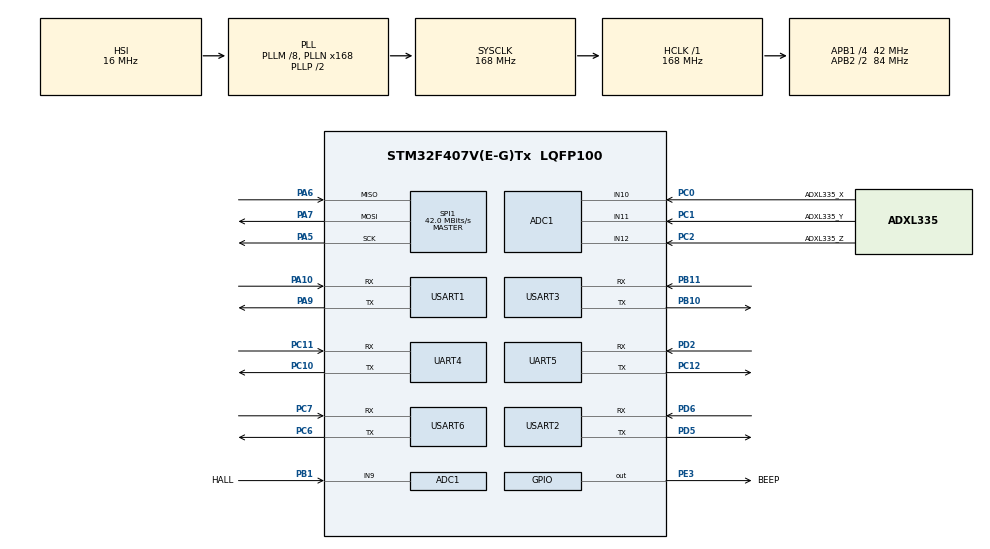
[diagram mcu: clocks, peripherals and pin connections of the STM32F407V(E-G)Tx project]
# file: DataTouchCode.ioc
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ADC1.Channel-0\#ChannelRegularConversion=ADC_CHANNEL_10
ADC1.NbrOfConversionFlag=1
ADC1.Rank-0\#ChannelRegularConversion=1
ADC1.SamplingTime-0\#ChannelRegularConversion=ADC_SAMPLETIME_3CYCLES
ADC1.master=1
Dma.Request0=UART5_RX
Dma.Request1=UART5_TX
Dma.Request2=USART2_RX
Dma.Request3=USART2_TX
Dma.Request4=USART6_RX
Dma.Request5=USART6_TX
Dma.UART5_RX.0.Direction=DMA_PERIPH_TO_MEMORY
Dma.UART5_RX.0.FIFOMode=DMA_FIFOMODE_DISABLE
Dma.UART5_RX.0.Instance=DMA1_Stream0
Dma.UART5_RX.0.MemDataAlignment=DMA_MDATAALIGN_BYTE
Dma.UART5_RX.0.MemInc=DMA_MINC_ENABLE
Dma.UART5_RX.0.Mode=DMA_CIRCULAR
Dma.UART5_RX.0.PeriphDataAlignment=DMA_PDATAALIGN_BYTE
Dma.UART5_RX.0.PeriphInc=DMA_PINC_DISABLE
Dma.UART5_RX.0.Priority=DMA_PRIORITY_LOW
Dma.UART5_TX.1.Direction=DMA_MEMORY_TO_PERIPH
Dma.UART5_TX.1.FIFOMode=DMA_FIFOMODE_DISABLE
Dma.UART5_TX.1.Instance=DMA1_Stream7
Dma.UART5_TX.1.MemDataAlignment=DMA_MDATAALIGN_BYTE
Dma.UART5_TX.1.MemInc=DMA_MINC_ENABLE
Dma.UART5_TX.1.Mode=DMA_NORMAL
Dma.UART5_TX.1.PeriphDataAlignment=DMA_PDATAALIGN_BYTE
Dma.UART5_TX.1.PeriphInc=DMA_PINC_DISABLE
Dma.UART5_TX.1.Priority=DMA_PRIORITY_LOW
Dma.USART2_RX.2.Direction=DMA_PERIPH_TO_MEMORY
Dma.USART2_RX.2.FIFOMode=DMA_FIFOMODE_DISABLE
Dma.USART2_RX.2.Instance=DMA1_Stream5
Dma.USART2_RX.2.MemDataAlignment=DMA_MDATAALIGN_BYTE
Dma.USART2_RX.2.MemInc=DMA_MINC_ENABLE
Dma.USART2_RX.2.Mode=DMA_CIRCULAR
Dma.USART2_RX.2.PeriphDataAlignment=DMA_PDATAALIGN_BYTE
Dma.USART2_RX.2.PeriphInc=DMA_PINC_DISABLE
Dma.USART2_RX.2.Priority=DMA_PRIORITY_LOW
Dma.USART2_TX.3.Direction=DMA_MEMORY_TO_PERIPH
Dma.USART2_TX.3.FIFOMode=DMA_FIFOMODE_DISABLE
Dma.USART2_TX.3.Instance=DMA1_Stream6
Dma.USART2_TX.3.MemDataAlignment=DMA_MDATAALIGN_BYTE
Dma.USART2_TX.3.MemInc=DMA_MINC_ENABLE
Dma.USART2_TX.3.Mode=DMA_NORMAL
Dma.USART2_TX.3.PeriphDataAlignment=DMA_PDATAALIGN_BYTE
Dma.USART2_TX.3.PeriphInc=DMA_PINC_DISABLE
Dma.USART2_TX.3.Priority=DMA_PRIORITY_LOW
Dma.USART6_RX.4.Direction=DMA_PERIPH_TO_MEMORY
Dma.USART6_RX.4.FIFOMode=DMA_FIFOMODE_DISABLE
Dma.USART6_RX.4.Instance=DMA2_Stream1
Dma.USART6_RX.4.MemDataAlignment=DMA_MDATAALIGN_BYTE
Dma.USART6_RX.4.MemInc=DMA_MINC_ENABLE
Dma.USART6_RX.4.Mode=DMA_CIRCULAR
Dma.USART6_RX.4.PeriphDataAlignment=DMA_PDATAALIGN_BYTE
Dma.USART6_RX.4.PeriphInc=DMA_PINC_DISABLE
Dma.USART6_RX.4.Priority=DMA_PRIORITY_LOW
Dma.USART6_TX.5.Direction=DMA_MEMORY_TO_PERIPH
Dma.USART6_TX.5.FIFOMode=DMA_FIFOMODE_DISABLE
Dma.USART6_TX.5.Instance=DMA2_Stream6
Dma.USART6_TX.5.MemDataAlignment=DMA_MDATAALIGN_BYTE
Dma.USART6_TX.5.MemInc=DMA_MINC_ENABLE
Dma.USART6_TX.5.Mode=DMA_NORMAL
Dma.USART6_TX.5.PeriphDataAlignment=DMA_PDATAALIGN_BYTE
Dma.USART6_TX.5.PeriphInc=DMA_PINC_DISABLE
Dma.USART6_TX.5.Priority=DMA_PRIORITY_LOW
FREERTOS.Tasks01=MotorTask,33,1024,StartMotorTask,As weak,NULL,Static,MotorTaskBuffer,MotorTaskControlBlock;ServiceTask,8,512,StartServiceTask,As weak,NULL,Static,ServiceTaskBuffer,ServiceTaskControlBlock
Mcu.Family=STM32F4
Mcu.Name=STM32F407V(E-G)Tx
Mcu.Package=LQFP100
NVIC.DMA1_Stream0_IRQn=true\:6\:0\:true\:false\:true\:true\:false\:true\:true
NVIC.DMA1_Stream7_IRQn=true\:6\:0\:true\:false\:true\:true\:false\:true\:true
NVIC.DMA2_Stream1_IRQn=true\:6\:0\:true\:false\:true\:true\:false\:true\:true
NVIC.DMA1_Stream5_IRQn=true\:6\:0\:true\:false\:true\:true\:false\:true\:true
NVIC.DMA2_Stream6_IRQn=true\:6\:0\:true\:false\:true\:true\:false\:true\:true
NVIC.DMA1_Stream6_IRQn=true\:6\:0\:true\:false\:true\:true\:false\:true\:true
NVIC.PriorityGroup=NVIC_PRIORITYGROUP_4
NVIC.TIM6_DAC_IRQn=true\:15\:0\:false\:false\:true\:false\:false\:true\:true
NVIC.TimeBase=TIM6_DAC_IRQn
NVIC.TimeBaseIP=TIM6
NVIC.UART5_IRQn=true\:6\:0\:true\:false\:true\:true\:false\:true\:true
NVIC.USART2_IRQn=true\:6\:0\:true\:false\:true\:true\:false\:true\:true
NVIC.USART6_IRQn=true\:6\:0\:true\:false\:true\:true\:false\:true\:true
PA10.Mode=Asynchronous
PA10.Signal=USART1_RX
PA13.Mode=Serial_Wire
PA13.Signal=SYS_JTMS-SWDIO
PA14.Mode=Serial_Wire
PA14.Signal=SYS_JTCK-SWCLK
PA5.Mode=Full_Duplex_Master
PA5.Signal=SPI1_SCK
PA6.Mode=Full_Duplex_Master
PA6.Signal=SPI1_MISO
PA7.Mode=Full_Duplex_Master
PA7.Signal=SPI1_MOSI
PA9.Mode=Asynchronous
PA9.Signal=USART1_TX
PB1.GPIO_Label=HALL
PB1.Signal=ADCx_IN9
PB10.Mode=Asynchronous
PB10.Signal=USART3_TX
PB11.Mode=Asynchronous
PB11.Signal=USART3_RX
PC0.GPIO_Label=ADXL335_X
PC0.Signal=ADCx_IN10
PC1.GPIO_Label=ADXL335_Y
PC1.Signal=ADCx_IN11
PC10.Mode=Asynchronous
PC10.Signal=UART4_TX
PC11.Mode=Asynchronous
PC11.Signal=UART4_RX
PC12.Mode=Asynchronous
PC12.Signal=UART5_TX
PC2.GPIO_Label=ADXL335_Z
PC2.Signal=ADCx_IN12
PC6.Mode=Asynchronous
PC6.Signal=USART6_TX
PC7.Mode=Asynchronous
PC7.Signal=USART6_RX
PD2.Mode=Asynchronous
PD2.Signal=UART5_RX
PD5.Mode=Asynchronous
PD5.Signal=USART2_TX
PD6.Mode=Asynchronous
PD6.Signal=USART2_RX
PE3.GPIO_Label=BEEP
PE3.Signal=GPIO_Output
PH0-OSC_IN.Mode=HSE-External-Oscillator
PH0-OSC_IN.Signal=RCC_OSC_IN
PH1-OSC_OUT.Mode=HSE-External-Oscillator
PH1-OSC_OUT.Signal=RCC_OSC_OUT
ProjectManager.HeapSize=0x200
ProjectManager.StackSize=0x400
ProjectManager.TargetToolchain=CMake
RCC.48MHZClocksFreq_Value=84000000
RCC.AHBFreq_Value=168000000
RCC.APB1CLKDivider=RCC_HCLK_DIV4
RCC.APB1Freq_Value=42000000
RCC.APB1TimFreq_Value=84000000
RCC.APB2CLKDivider=RCC_HCLK_DIV2
RCC.APB2Freq_Value=84000000
RCC.APB2TimFreq_Value=168000000
RCC.CortexFreq_Value=168000000
RCC.HCLKFreq_Value=168000000
RCC.HSE_VALUE=25000000
RCC.HSI_VALUE=16000000
RCC.LSE_VALUE=32768
RCC.PLLM=8
RCC.PLLN=168
RCC.SYSCLKFreq_VALUE=168000000
RCC.SYSCLKSource=RCC_SYSCLKSOURCE_PLLCLK
RCC.VCOOutputFreq_Value=336000000
SH.ADCx_IN10.0=ADC1_IN10,IN10
SH.ADCx_IN11.0=ADC1_IN11,IN11
SH.ADCx_IN12.0=ADC1_IN12,IN12
SH.ADCx_IN9.0=ADC1_IN9,IN9
SPI1.CalculateBaudRate=42.0 MBits/s
SPI1.Direction=SPI_DIRECTION_2LINES
SPI1.Mode=SPI_MODE_MASTER
SPI1.VirtualType=VM_MASTER
UART4.VirtualMode=Asynchronous
UART5.VirtualMode=Asynchronous
USART1.VirtualMode=VM_ASYNC
USART2.VirtualMode=VM_ASYNC
USART3.VirtualMode=VM_ASYNC
USART6.VirtualMode=VM_ASYNC
VP_FREERTOS_VS_CMSIS_V2.Mode=CMSIS_V2
VP_SYS_VS_tim6.Mode=TIM6
VP_TIM2_VS_ClockSourceINT.Mode=Internal
board=custom
TIM2.Prescaler=83
TIM2.Period=1999
NVIC.TIM2_IRQn=true\:6\:0\:true\:false\:true\:true\:false\:true\:true
NVIC.USART3_IRQn=true\:6\:0\:false\:false\:true\:true\:true\:true

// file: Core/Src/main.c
/* USER CODE BEGIN Header */
/**
  ******************************************************************************
  * @file           : main.c
  * @brief          : Main program body
  ******************************************************************************
  * @attention
  *
  * Copyright (c) 2026 STMicroelectronics.
  * All rights reserved.
  *
  * This software is licensed under terms that can be found in the LICENSE file
  * in the root directory of this software component.
  * If no LICENSE file comes with this software, it is provided AS-IS.
  *
  ******************************************************************************
  */
/* USER CODE END Header */
#include "main.h"
#include "cmsis_os.h"
#include "adc.h"
#include "dma.h"
#include "spi.h"
#include "tim.h"
#include "usart.h"
#include "gpio.h"

/* USER CODE BEGIN Includes */
#include "board.h"

/* USER CODE END Includes */

void SystemClock_Config(void);
void MX_FREERTOS_Init(void);

int main(void)
{

  /* MCU Configuration--------------------------------------------------------*/

  /* Reset of all peripherals, Initializes the Flash interface and the Systick. */
  HAL_Init();

  /* Configure the system clock */
  SystemClock_Config();

  /* Initialize all configured peripherals */
  MX_GPIO_Init();
  MX_DMA_Init();
  MX_ADC1_Init();
  MX_SPI1_Init();
  MX_UART4_Init();
  MX_UART5_Init();
  MX_USART1_UART_Init();
  MX_USART2_UART_Init();
  MX_USART3_UART_Init();
  MX_USART6_UART_Init();
  MX_TIM2_Init();
  /* USER CODE BEGIN 2 */
  Board_Init();

  /* USER CODE END 2 */

  /* Init scheduler */
  osKernelInitialize();  /* Call init function for freertos objects (in cmsis_os2.c) */
  MX_FREERTOS_Init();

  /* Start scheduler */
  osKernelStart();

  /* We should never get here as control is now taken by the scheduler */

  /* Infinite loop */
  while (1)
  {

  }
}

void SystemClock_Config(void)
{
  RCC_OscInitTypeDef RCC_OscInitStruct = {0};
  RCC_ClkInitTypeDef RCC_ClkInitStruct = {0};

  /** Configure the main internal regulator output voltage
  */
  __HAL_RCC_PWR_CLK_ENABLE();
  __HAL_PWR_VOLTAGESCALING_CONFIG(PWR_REGULATOR_VOLTAGE_SCALE1);

  /** Initializes the RCC Oscillators according to the specified parameters
  * in the RCC_OscInitTypeDef structure.
  */
  RCC_OscInitStruct.OscillatorType = RCC_OSCILLATORTYPE_HSI;
  RCC_OscInitStruct.HSIState = RCC_HSI_ON;
  RCC_OscInitStruct.HSICalibrationValue = RCC_HSICALIBRATION_DEFAULT;
  RCC_OscInitStruct.PLL.PLLState = RCC_PLL_ON;
  RCC_OscInitStruct.PLL.PLLSource = RCC_PLLSOURCE_HSI;
  RCC_OscInitStruct.PLL.PLLM = 8;
  RCC_OscInitStruct.PLL.PLLN = 168;
  RCC_OscInitStruct.PLL.PLLP = RCC_PLLP_DIV2;
  RCC_OscInitStruct.PLL.PLLQ = 4;
  if (HAL_RCC_OscConfig(&RCC_OscInitStruct) != HAL_OK)
  {
    Error_Handler();
  }

  /** Initializes the CPU, AHB and APB buses clocks
  */
  RCC_ClkInitStruct.ClockType = RCC_CLOCKTYPE_HCLK|RCC_CLOCKTYPE_SYSCLK
                              |RCC_CLOCKTYPE_PCLK1|RCC_CLOCKTYPE_PCLK2;
  RCC_ClkInitStruct.SYSCLKSource = RCC_SYSCLKSOURCE_PLLCLK;
  RCC_ClkInitStruct.AHBCLKDivider = RCC_SYSCLK_DIV1;
  RCC_ClkInitStruct.APB1CLKDivider = RCC_HCLK_DIV4;
  RCC_ClkInitStruct.APB2CLKDivider = RCC_HCLK_DIV2;

  if (HAL_RCC_ClockConfig(&RCC_ClkInitStruct, FLASH_LATENCY_5) != HAL_OK)
  {
    Error_Handler();
  }
}

void HAL_TIM_PeriodElapsedCallback(TIM_HandleTypeDef *htim)
{
  if (htim->Instance == TIM6)
  {
    HAL_IncTick();
  }
  /* USER CODE BEGIN Callback 1 */
  Board_TimerCallback(htim);

  /* USER CODE END Callback 1 */
}

void Error_Handler(void)
{
  __disable_irq();
  while (1)
  {
  }
}
